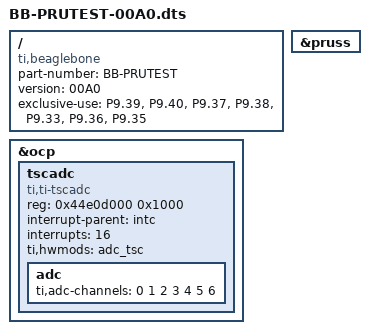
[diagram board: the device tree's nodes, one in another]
/dts-v1/;
/plugin/;

/ {
	compatible = "ti,beaglebone", "ti,beaglebone-black";

	/* identification */
	part-number = "BB-PRUTEST";
	version = "00A0";

	/* state the resources this cape uses */
	exclusive-use =
		/* the pin header P9 uses */
		"P9.39", /* AIN0 */
		"P9.40", /* AIN1 */
		"P9.37", /* AIN2 */
		"P9.38", /* AIN3 */
		"P9.33", /* AIN4 */
		"P9.36", /* AIN5 */
		"P9.35"; /* AIN6 */

	fragment@0{
		target = <&pruss>;
		__overlay__{
			status = "okay";
			pinctrl-names = "default";
		};
	};

	fragment@1 {
		target = <&ocp>;
		__overlay__ {			
			#address-cells = <1>;
			#size-cells = <1>;							

			tscadc {
				compatible = "ti,ti-tscadc";
				reg = <0x44e0d000 0x1000>;

				interrupt-parent = <&intc>;
				interrupts = <16>;
				ti,hwmods = "adc_tsc";
				status = "okay";

				adc {
					ti,adc-channels = <0 1 2 3 4 5 6>;
				};
			};

		};
	};
};
